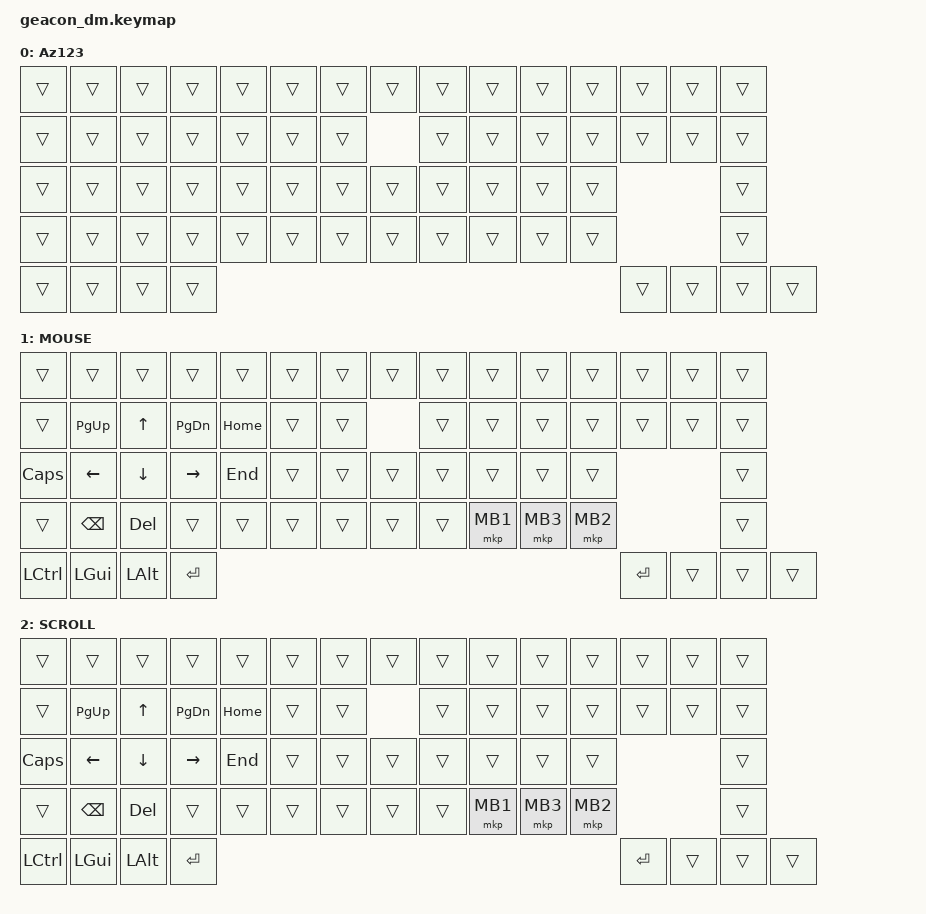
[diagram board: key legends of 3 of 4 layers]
#include <behaviors.dtsi>
#include <dt-bindings/zmk/keys.h>
#include <dt-bindings/zmk/pointing.h>
#include <dt-bindings/zmk/bt.h>
#include <behaviors/rgbled_widget.dtsi>

#define MOUSE 1
#define SCROLL 2
#define BT 3

&mt {
   flavor = "tap-preferred";
   quick_tap_ms = <125>;
   tapping_term_ms = <250>;
};
 
/ {
    macros {
        to_layer_0: to_layer_0 {
            compatible = "zmk,behavior-macro-one-param";
            #binding-cells = <1>;
            bindings = <&to 0 &macro_param_1to1 &kp MACRO_PLACEHOLDER>;
            label = "TO_LAYER_0";
        };
    };

    behaviors {
        lt_to_layer_0: lt_to_layer_0 {
            compatible = "zmk,behavior-hold-tap";
            label = "LAYER_TAP_TO_0";
            bindings = <&mo>, <&to_layer_0>;

            #binding-cells = <2>;
            tapping-term-ms = <200>;
        };
    }; 
 
   keymap {
       compatible = "zmk,keymap";
       default_layer {
           label = "Az123";
           bindings = <
&trans    &trans    &trans     &trans     &trans     &trans       &trans    &trans     &trans     &trans     &trans    &trans      &trans      &trans &trans
&trans    &trans    &trans     &trans     &trans     &trans       &trans    &trans     &trans     &trans     &trans    &trans      &trans          &trans
&trans    &trans    &trans     &trans     &trans     &trans       &trans    &trans     &trans     &trans     &trans    &trans                      &trans
&trans    &trans    &trans     &trans     &trans     &trans       &trans    &trans     &trans     &trans     &trans    &trans                      &trans
&trans    &trans    &trans     &trans     &trans                                                                                          &trans &trans &trans
>;
       };

       mouse_layer {
           display-name = "MOUSE";    
           label = "MOUSE";
           bindings = <
&trans    &trans    &trans     &trans     &trans     &trans       &trans    &trans     &trans     &trans     &trans    &trans      &trans      &trans &trans
&trans    &kp PG_UP &kp UP     &kp PG_DN  &kp HOME   &trans       &trans    &trans     &trans     &trans     &trans    &trans      &trans          &trans
&kp CAPS  &kp LEFT  &kp DOWN   &kp RIGHT  &kp END    &trans       &trans    &trans     &trans     &trans     &trans    &trans                      &trans
&trans    &kp BKSP  &kp DEL    &trans     &trans     &trans       &trans    &trans     &trans     &mkp MB1   &mkp MB3  &mkp MB2                    &trans
&kp LCTL   &kp LGUI   &kp LALT         &kp ENTER     &kp ENTER                                                                          &trans   &trans   &trans
>;
       };

       scroll_layer {
           display-name = "SCROLL";    
           label = "SCROLL";
           bindings = <
&trans    &trans    &trans     &trans     &trans     &trans       &trans    &trans     &trans     &trans     &trans    &trans      &trans      &trans &trans
&trans    &kp PG_UP &kp UP     &kp PG_DN  &kp HOME   &trans       &trans    &trans     &trans     &trans     &trans    &trans      &trans          &trans
&kp CAPS  &kp LEFT  &kp DOWN   &kp RIGHT  &kp END    &trans       &trans    &trans     &trans     &trans     &trans    &trans                      &trans
&trans    &kp BKSP  &kp DEL    &trans     &trans     &trans       &trans    &trans     &trans     &mkp MB1   &mkp MB3  &mkp MB2                    &trans
&kp LCTL   &kp LGUI   &kp LALT         &kp ENTER     &kp ENTER                                                                          &trans   &trans   &trans
>;
       };

        bt_layer {
           display-name = "BT";    
           label = "BT";
           bindings = <
&bt BT_CLR     &bt BT_SEL 0 &bt BT_SEL 1 &bt BT_SEL 2 &bt BT_SEL 3 &bt BT_SEL 4  &trans  &trans  &trans  &trans  &trans  &trans  &trans  &trans   &trans &trans
&bt BT_CLR_ALL &trans       &trans       &trans       &trans       &trans        &trans  &trans  &trans  &trans  &trans  &trans  &trans              &trans
&trans         &trans       &trans       &trans       &trans       &trans        &trans  &trans  &trans  &trans  &trans  &trans                      &trans
&trans         &trans       &trans       &trans       &trans       &trans        &trans  &trans  &trans  &trans  &trans  &trans                      &trans
&trans         &trans       &trans       &trans       &trans                                                                                &trans   &trans   &trans
>;
    };
  };
};

/ {
    aliases {
        led-red = &led0;
        led-green = &led1;
        led-blue = &led2;
    };

    leds {
        compatible = "gpio-leds";
        status = "okay";
        led0: led_0 {
            gpios = <&gpio0 26 GPIO_ACTIVE_LOW>;  // red LED, connected to P0.26
        };
        led1: led_1 {
            gpios = <&gpio0 30 GPIO_ACTIVE_LOW>;  // green LED, connected to P0.30
        };
        led2: led_2 {
            gpios = <&gpio0 6 GPIO_ACTIVE_LOW>;  // blue LED, connected to P0.06
        };
    };
};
